VERSION "dbc-export 1 2025.20.8"

NS_ :

BS_:

BU_: DAS GTW HVP ICR PCS SCCM VCFRONT VCLEFT VCRIGHT VCSEC

BO_ 1001 DAS_bodyControls: 8 DAS
 SG_ DAS_headlightRequest : 0|2@1+ (1,0) [0|3] "" Vector__XXX
 SG_ DAS_hazardLightRequest : 2|2@1+ (1,0) [0|2] "" Vector__XXX
 SG_ DAS_wiperSpeed : 4|4@1+ (1,0) [0|15] "" Vector__XXX
 SG_ DAS_turnIndicatorRequest : 8|3@1+ (1,0) [0|7] "" Vector__XXX
 SG_ DAS_highLowBeamDecision : 11|2@1+ (1,0) [0|2] "" Vector__XXX
 SG_ DAS_heaterRequest : 13|2@1+ (1,0) [1|3] "" Vector__XXX
 SG_ DAS_highLowBeamOffReason : 15|3@1+ (1,0) [0|7] "" Vector__XXX
 SG_ DAS_forwardCamHeaterDutyCycle : 18|4@1+ (0.06666667,0) [0|1] "-" Vector__XXX
 SG_ DAS_dynamicBrakeLightRequest : 22|1@1+ (1,0) [0|1] "" Vector__XXX
 SG_ DAS_radarHeaterRequest : 23|1@1+ (1,0) [0|1] "" Vector__XXX
 SG_ DAS_ahlbOverride : 24|1@1+ (1,0) [0|1] "" Vector__XXX
 SG_ DAS_mirrorFoldRequest : 25|2@1+ (1,0) [0|2] "" Vector__XXX
 SG_ DAS_wiperWashRequest : 27|1@1+ (1,0) [0|1] "" Vector__XXX
 SG_ DAS_ulcConfirmationRequestActive : 28|1@1+ (1,0) [0|1] "" Vector__XXX
 SG_ DAS_overrideWiperSetting : 29|1@1+ (1,0) [0|1] "" Vector__XXX
 SG_ DAS_autoWiperState : 30|3@1+ (1,0) [0|7] "" Vector__XXX
 SG_ DAS_turnIndicatorRequestReason : 33|5@1+ (1,0) [0|31] "" Vector__XXX
 SG_ DAS_forwardRadarPowerRequest : 38|1@1+ (1,0) [0|1] "" Vector__XXX
 SG_ DAS_driverDomeLightRequest : 39|1@1+ (1,0) [0|1] "" Vector__XXX
 SG_ DAS_drivePowerStateRequest : 43|1@1+ (1,0) [0|1] "" Vector__XXX
 SG_ DAS_enableIcrDataCollection : 44|1@1+ (1,0) [0|1] "" Vector__XXX
 SG_ DAS_rPillarCamHeaterDutyCycle : 45|4@1+ (0.06666667,0) [0|1] "-" Vector__XXX
 SG_ DAS_adaptiveHighBeamIsFaulted : 49|1@1+ (1,0) [0|1] "" Vector__XXX
 SG_ DAS_restrictDoorReleaseLeft : 50|1@1+ (1,0) [0|1] "" Vector__XXX
 SG_ DAS_restrictDoorReleaseRight : 51|1@1+ (1,0) [0|1] "" Vector__XXX
 SG_ DAS_bodyControlsCounter : 52|4@1+ (1,0) [0|15] "" Vector__XXX
 SG_ DAS_bodyControlsChecksum : 56|8@1+ (1,0) [0|255] "" Vector__XXX

BO_ 784 HVP_info: 8 HVP
 SG_ HVP_infoIndex M : 0|8@1+ (1,0) [0|255] "" Vector__XXX
 SG_ HVP_buildType m10 : 8|3@1+ (1,0) [0|7] "" Vector__XXX
 SG_ HVP_buildConfigId m10 : 16|16@1+ (1,0) [0|65535] "" Vector__XXX
 SG_ HVP_hardwareId m10 : 32|16@1+ (1,0) [0|65535] "" Vector__XXX
 SG_ HVP_componentId m10 : 48|16@1+ (1,0) [0|65535] "" Vector__XXX
 SG_ HVP_pcbaId m11 : 16|8@1+ (1,0) [0|255] "" Vector__XXX
 SG_ HVP_assemblyId m11 : 24|8@1+ (1,0) [0|255] "" Vector__XXX
 SG_ HVP_usageId m11 : 32|16@1+ (1,0) [0|65535] "" Vector__XXX
 SG_ HVP_subUsageId m11 : 48|16@1+ (1,0) [0|65535] "" Vector__XXX
 SG_ HVP_platformType m13 : 8|8@1+ (1,0) [0|255] "" Vector__XXX
 SG_ HVP_appCrc m13 : 32|32@1+ (1,0) [0|4294967295] "" Vector__XXX
 SG_ HVP_appGitHash m17 : 8|56@1+ (1,0) [0|7.20575940379e+16] "" Vector__XXX
 SG_ HVP_bootGitHash m18 : 8|56@1+ (1,0) [0|7.20575940379e+16] "" Vector__XXX
 SG_ HVP_bootUdsProtoVersion m20 : 8|8@1+ (1,0) [0|255] "" Vector__XXX
 SG_ HVP_bootCrc m20 : 32|32@1+ (1,0) [0|4294967295] "" Vector__XXX

BO_ 941 ICR_info: 8 ICR
 SG_ ICR_infoIndex M : 0|8@1+ (1,0) [0|255] "" Vector__XXX
 SG_ ICR_infoBuildType m10 : 8|3@1+ (1,0) [0|7] "" Vector__XXX
 SG_ ICR_infoPcbaId m11 : 32|8@1+ (1,0) [0|255] "" Vector__XXX
 SG_ ICR_infoAssemblyId m11 : 40|8@1+ (1,0) [0|255] "" Vector__XXX
 SG_ ICR_infoUsageId m11 : 48|16@1+ (1,0) [0|65535] "" Vector__XXX
 SG_ ICR_infoAppCrc m13 : 8|32@1+ (1,0) [0|4294967295] "" Vector__XXX
 SG_ ICR_infoBoardPartNumber17 m25 : 8|56@1+ (1,0) [0|7.20575940379e+16] "" Vector__XXX
 SG_ ICR_infoBoardPartNumber814 m26 : 8|56@1+ (1,0) [0|7.20575940379e+16] "" Vector__XXX
 SG_ ICR_infoBoardPartNumber1520 m27 : 8|48@1+ (1,0) [0|281474976710655] "" Vector__XXX

BO_ 964 PCS_info: 8 PCS
 SG_ PCS_infoIndex M : 0|8@1+ (1,0) [0|255] "" Vector__XXX
 SG_ PCS_buildType m10 : 8|8@1+ (1,0) [0|255] "" Vector__XXX
 SG_ PCS_buildConfigId m10 : 16|16@1+ (1,0) [0|65535] "" Vector__XXX
 SG_ PCS_hardwareId m10 : 32|16@1+ (1,0) [0|65535] "" Vector__XXX
 SG_ PCS_componentId m10 : 48|16@1+ (1,0) [0|65535] "" Vector__XXX
 SG_ PCS_pcbaId m11 : 16|8@1+ (1,0) [0|255] "" Vector__XXX
 SG_ PCS_assemblyId m11 : 24|8@1+ (1,0) [0|255] "" Vector__XXX
 SG_ PCS_usageId m11 : 32|16@1+ (1,0) [0|65535] "" Vector__XXX
 SG_ PCS_subUsageId m11 : 48|16@1+ (1,0) [0|65535] "" Vector__XXX
 SG_ PCS_platformType m13 : 8|8@1+ (1,0) [0|255] "" Vector__XXX
 SG_ PCS_appCrc m13 : 32|32@1+ (1,0) [0|4294967295] "" Vector__XXX
 SG_ PCS_cpu2AppCrc m16 : 32|32@1+ (1,0) [0|4294967295] "" Vector__XXX
 SG_ PCS_appGitHash m17 : 8|56@1+ (1,0) [0|7.20575940379e+16] "" Vector__XXX
 SG_ PCS_bootGitHash m18 : 8|56@1+ (1,0) [0|7.20575940379e+16] "" Vector__XXX
 SG_ PCS_bootUdsProtoVersion m20 : 8|8@1+ (1,0) [0|255] "" Vector__XXX
 SG_ PCS_bootCrc m20 : 32|32@1+ (1,0) [0|4294967295] "" Vector__XXX

BO_ 816 SCCM_info: 8 SCCM
 SG_ SCCM_infoIndex M : 0|8@1+ (1,0) [0|255] "" Vector__XXX
 SG_ SCCM_infoBuildType m10 : 8|8@1+ (1,0) [0|255] "" Vector__XXX
 SG_ SCCM_infoBuildConfigId m10 : 16|16@1+ (1,0) [0|65535] "" Vector__XXX
 SG_ SCCM_infoHardwareId m10 : 32|16@1+ (1,0) [0|65535] "" Vector__XXX
 SG_ SCCM_infoComponentId m10 : 48|16@1+ (1,0) [0|65535] "" Vector__XXX
 SG_ SCCM_infoPcbaId m11 : 16|8@1+ (1,0) [0|255] "" Vector__XXX
 SG_ SCCM_infoAssemblyId m11 : 24|8@1+ (1,0) [0|255] "" Vector__XXX
 SG_ SCCM_infoUsageId m11 : 32|16@1+ (1,0) [0|65535] "" Vector__XXX
 SG_ SCCM_infoSubUsageId m11 : 48|16@1+ (1,0) [0|65535] "" Vector__XXX
 SG_ SCCM_infoPlatformType m13 : 8|8@1+ (1,0) [0|255] "" Vector__XXX
 SG_ SCCM_infoAppCrc m13 : 39|32@0+ (1,0) [0|4294967295] "" Vector__XXX
 SG_ SCCM_infoBootSvnRev m14 : 8|24@1+ (1,0) [0|16777215] "" Vector__XXX
 SG_ SCCM_infoBootSvnUrlHash m14 : 32|32@1+ (1,0) [0|4294967295] "" Vector__XXX
 SG_ SCCM_infoSubcomponent1Version m16 : 16|32@1+ (1,0) [0|4294967295] "" Vector__XXX
 SG_ SCCM_infoAppSvnHash m17 : 8|56@1+ (1,0) [0|7.20575940379e+16] "" Vector__XXX
 SG_ SCCM_infoBootSvnHash m18 : 8|56@1+ (1,0) [0|7.20575940379e+16] "" Vector__XXX
 SG_ SCCM_infoUdsProtoVersion m20 : 8|8@1+ (1,0) [0|255] "" Vector__XXX
 SG_ SCCM_infoBootCrc m20 : 32|32@1+ (1,0) [0|4294967295] "" Vector__XXX

BO_ 663 UI_suspensionControl: 8 GTW
 SG_ UI_adaptiveRideRequest : 3|2@1+ (1,0) [0|3] "" Vector__XXX
 SG_ UI_geofenceLevelingRequest : 7|3@1+ (1,0) [0|7] "" Vector__XXX

BO_ 957 VCFRONT_parkedEnergyLoss: 8 VCFRONT
 SG_ VCFRONT_energyLossIndex M : 0|3@1+ (1,0) [0|7] "" Vector__XXX
 SG_ VCFRONT_userEnergyLossSinceDrive m1 : 8|14@1+ (0.01,0) [0|163.83] "kWh" Vector__XXX
 SG_ VCFRONT_preconditioningEner_0001 m1 : 22|14@1+ (0.01,0) [0|163.83] "kWh" Vector__XXX
 SG_ VCFRONT_cabinOverheatEnergy_0001 m1 : 36|14@1+ (0.01,0) [0|163.83] "kWh" Vector__XXX
 SG_ VCFRONT_mobileAppEnergyLoss_0001 m1 : 50|14@1+ (0.01,0) [0|163.83] "kWh" Vector__XXX
 SG_ VCFRONT_summonStandbyEnergy_0001 m2 : 8|14@1+ (0.01,0) [0|163.83] "kWh" Vector__XXX
 SG_ VCFRONT_sentryModeEnergyLos_0001 m2 : 22|14@1+ (0.01,0) [0|163.83] "kWh" Vector__XXX
 SG_ VCFRONT_backgroundEnergyLos_0001 m2 : 36|14@1+ (0.01,0) [0|163.83] "kWh" Vector__XXX
 SG_ VCFRONT_evapDryingEnergyLos_0001 m2 : 50|14@1+ (0.01,0) [0|163.83] "kWh" Vector__XXX
 SG_ VCFRONT_userEnergyLossSinceCharg m3 : 8|14@1+ (0.01,0) [0|163.83] "kWh" Vector__XXX
 SG_ VCFRONT_preconditioningEnergyLos m3 : 22|14@1+ (0.01,0) [0|163.83] "kWh" Vector__XXX
 SG_ VCFRONT_cabinOverheatEnergyLossS m3 : 36|14@1+ (0.01,0) [0|163.83] "kWh" Vector__XXX
 SG_ VCFRONT_mobileAppEnergyLossSince m3 : 50|14@1+ (0.01,0) [0|163.83] "kWh" Vector__XXX
 SG_ VCFRONT_summonStandbyEnergyLossS m4 : 8|14@1+ (0.01,0) [0|163.83] "kWh" Vector__XXX
 SG_ VCFRONT_sentryModeEnergyLossSinc m4 : 22|14@1+ (0.01,0) [0|163.83] "kWh" Vector__XXX
 SG_ VCFRONT_backgroundEnergyLossSinc m4 : 36|14@1+ (0.01,0) [0|163.83] "kWh" Vector__XXX
 SG_ VCFRONT_evapDryingEnergyLossSinc m4 : 50|14@1+ (0.01,0) [0|163.83] "kWh" Vector__XXX

BO_ 507 VCLEFT_TLCStatus: 8 VCLEFT
 SG_ VCLEFT_TLCStatusIndex M : 0|2@1+ (1,0) [0|3] "" Vector__XXX
 SG_ VCLEFT_TLCTemperature m1 : 2|8@1- (1,68) [-59|195] "degC" Vector__XXX
 SG_ VCLEFT_TLCLeftTurnVoltage m1 : 10|8@1+ (0.1,0) [0|25.4] "V" Vector__XXX
 SG_ VCLEFT_TLCRightTurnVoltage m1 : 18|8@1+ (0.1,0) [0|25.4] "V" Vector__XXX
 SG_ VCLEFT_TLCState_LeftTurn m1 : 26|3@1+ (1,0) [0|7] "" Vector__XXX
 SG_ VCLEFT_TLCState_RightTurn m1 : 29|3@1+ (1,0) [0|7] "" Vector__XXX
 SG_ VCLEFT_TLCState_Tail m1 : 32|3@1+ (1,0) [0|7] "" Vector__XXX
 SG_ VCLEFT_TLCState_Stop m1 : 35|3@1+ (1,0) [0|7] "" Vector__XXX
 SG_ VCLEFT_TLCState_Fog m1 : 38|3@1+ (1,0) [0|7] "" Vector__XXX
 SG_ VCLEFT_TLCState_Reverse m1 : 41|3@1+ (1,0) [0|7] "" Vector__XXX

BO_ 291 VCRIGHT_doorStatus2: 8 VCRIGHT
 SG_ VCRIGHT_doorStatus2Index M : 0|1@1+ (1,0) [0|1] "" Vector__XXX
 SG_ VCRIGHT_frontLatchRelDuty m1 : 8|8@1+ (1,0) [0|255] "%" Vector__XXX
 SG_ VCRIGHT_BPillarCameraHeaterState m1 : 16|3@1+ (1,0) [1|7] "" Vector__XXX
 SG_ VCRIGHT_doorLatchAjarSwitchVolta m1 : 24|8@1+ (0.02,0) [0|5] "V" Vector__XXX
 SG_ VCRIGHT_doorLatchAjarSwitch_0001 m1 : 32|8@1+ (0.02,0) [0|5] "V" Vector__XXX
 SG_ VCRIGHT_BPillarCameraHeaterCurre m1 : 40|6@1+ (0.02,0) [0|1.24] "A" Vector__XXX
 SG_ VCRIGHT_mirrorTiltXOffset m1 : 48|8@1- (0.02,0) [-2.5|2.5] "V" Vector__XXX
 SG_ VCRIGHT_mirrorTiltYOffset m1 : 56|8@1- (0.02,0) [-2.5|2.5] "V" Vector__XXX

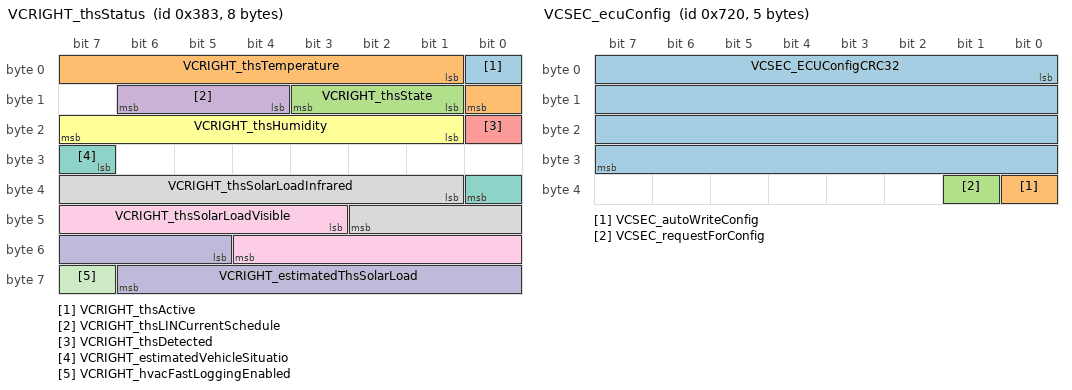
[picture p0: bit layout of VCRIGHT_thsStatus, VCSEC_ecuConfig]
BO_ 899 VCRIGHT_thsStatus: 8 VCRIGHT
 SG_ VCRIGHT_thsActive : 0|1@1+ (1,0) [0|1] "" Vector__XXX
 SG_ VCRIGHT_thsTemperature : 1|8@1+ (1,-40) [-40|150] "degC" Vector__XXX
 SG_ VCRIGHT_thsState : 9|3@1+ (1,0) [0|7] "" Vector__XXX
 SG_ VCRIGHT_thsLINCurrentSchedule : 12|3@1+ (1,0) [0|7] "" Vector__XXX
 SG_ VCRIGHT_thsDetected : 16|1@1+ (1,0) [0|1] "" Vector__XXX
 SG_ VCRIGHT_thsHumidity : 17|7@1+ (1,0) [0|100] "%" Vector__XXX
 SG_ VCRIGHT_estimatedVehicleSituatio : 31|2@1+ (1,0) [0|3] "" Vector__XXX
 SG_ VCRIGHT_thsSolarLoadInfrared : 33|10@1+ (2,0) [0|2044] "W/m2" Vector__XXX
 SG_ VCRIGHT_thsSolarLoadVisible : 43|10@1+ (2,0) [0|2044] "W/m2" Vector__XXX
 SG_ VCRIGHT_estimatedThsSolarLoad : 53|10@1+ (1,0) [0|1022] "W/m2" Vector__XXX
 SG_ VCRIGHT_hvacFastLoggingEnabled : 63|1@1+ (1,0) [0|1] "" Vector__XXX

BO_ 1066 VCSEC_TPMSConnectionData: 8 VCSEC
 SG_ VCSEC_TPMSSensorState0 : 0|3@1+ (1,0) [0|7] "" Vector__XXX
 SG_ VCSEC_TPMSRSSI0 : 3|7@1+ (1,-127) [-127|0] "dBm" Vector__XXX
 SG_ VCSEC_TPMSConnectionTypeCurrent0 : 10|2@1+ (1,0) [0|3] "" Vector__XXX
 SG_ VCSEC_TPMSConnectionTypeDesired0 : 12|2@1+ (1,0) [0|3] "" Vector__XXX
 SG_ VCSEC_TPMSSensorState1 : 14|3@1+ (1,0) [0|7] "" Vector__XXX
 SG_ VCSEC_TPMSRSSI1 : 17|7@1+ (1,-127) [-127|0] "dBm" Vector__XXX
 SG_ VCSEC_TPMSConnectionTypeCurrent1 : 24|2@1+ (1,0) [0|3] "" Vector__XXX
 SG_ VCSEC_TPMSConnectionTypeDesired1 : 26|2@1+ (1,0) [0|3] "" Vector__XXX
 SG_ VCSEC_TPMSSensorState2 : 28|3@1+ (1,0) [0|7] "" Vector__XXX
 SG_ VCSEC_TPMSRSSI2 : 31|7@1+ (1,-127) [-127|0] "dBm" Vector__XXX
 SG_ VCSEC_TPMSConnectionTypeCurrent2 : 38|2@1+ (1,0) [0|3] "" Vector__XXX
 SG_ VCSEC_TPMSConnectionTypeDesired2 : 40|2@1+ (1,0) [0|3] "" Vector__XXX
 SG_ VCSEC_TPMSSensorState3 : 42|3@1+ (1,0) [0|7] "" Vector__XXX
 SG_ VCSEC_TPMSRSSI3 : 45|7@1+ (1,-127) [-127|0] "dBm" Vector__XXX
 SG_ VCSEC_TPMSConnectionTypeCurrent3 : 52|2@1+ (1,0) [0|3] "" Vector__XXX
 SG_ VCSEC_TPMSConnectionTypeDesired3 : 54|2@1+ (1,0) [0|3] "" Vector__XXX
 SG_ VCSEC_TPMSSensorPresence0 : 56|2@1+ (1,0) [0|3] "" Vector__XXX
 SG_ VCSEC_TPMSSensorPresence1 : 58|2@1+ (1,0) [0|3] "" Vector__XXX
 SG_ VCSEC_TPMSSensorPresence2 : 60|2@1+ (1,0) [0|3] "" Vector__XXX
 SG_ VCSEC_TPMSSensorPresence3 : 62|2@1+ (1,0) [0|3] "" Vector__XXX

BO_ 1824 VCSEC_ecuConfig: 5 VCSEC
 SG_ VCSEC_ECUConfigCRC32 : 0|32@1+ (1,0) [0|4294967295] "" Vector__XXX
 SG_ VCSEC_autoWriteConfig : 32|1@1+ (1,0) [0|1] "" Vector__XXX
 SG_ VCSEC_requestForConfig : 33|1@1+ (1,0) [0|1] "" Vector__XXX

BO_TX_BU_ 1001 : DAS;
BO_TX_BU_ 784 : HVP;
BO_TX_BU_ 941 : ICR;
BO_TX_BU_ 964 : PCS;
BO_TX_BU_ 816 : SCCM;
BO_TX_BU_ 663 : GTW;
BO_TX_BU_ 957 : VCFRONT;
BO_TX_BU_ 507 : VCLEFT;
BO_TX_BU_ 291 : VCRIGHT;
BO_TX_BU_ 899 : VCRIGHT;
BO_TX_BU_ 1066 : VCSEC;
BO_TX_BU_ 1824 : VCSEC;

CM_ "Tesla Model Y CAN bus database; bus VEH (vehicle CAN); firmware 2025.20.8. Decoded CAN signal definitions (layout, scaling, units, value tables).";
CM_ BU_ DAS "Driver assistance computer";
CM_ BU_ GTW "Gateway";
CM_ BU_ HVP "High-voltage processor (pack contactor and isolation controller)";
CM_ BU_ ICR "ICR ECU";
CM_ BU_ PCS "Power conversion system (on-board charger and DC-DC converter)";
CM_ BU_ SCCM "Steering column control module";
CM_ BU_ VCFRONT "Front body controller";
CM_ BU_ VCLEFT "Left body controller";
CM_ BU_ VCRIGHT "Right body controller";
CM_ BU_ VCSEC "Vehicle security controller";
CM_ BO_ 1001 "Driver assistance computer message: body controls";
CM_ SG_ 1001 DAS_headlightRequest "The DAS request to the body controls ecu to turn on headlights.";
CM_ SG_ 1001 DAS_hazardLightRequest "The command from DAS to body controls to turn on the hazard lights; raw 3 = signal not available (SNA)";
CM_ SG_ 1001 DAS_wiperSpeed "The auto wiper algorithm speed request to the body controller.";
CM_ SG_ 1001 DAS_turnIndicatorRequest "Reports Driver Assistance System (DAS) request to body controls to turn on/off the left or right turn indicator.";
CM_ SG_ 1001 DAS_highLowBeamDecision "The output of the automatic high beam algorithm, to turn the highbeams on or off; raw 3 = signal not available (SNA)";
CM_ SG_ 1001 DAS_heaterRequest "The DAS request to the body controller to turn on the front glass heater in front of the triple camera; raw 0 = signal not available (SNA)";
CM_ SG_ 1001 DAS_highLowBeamOffReason "The reason why automatic high beams are surpressed; raw 5 = signal not available (SNA)";
CM_ SG_ 1001 DAS_forwardCamHeaterDutyCycle "Supplies the requested duty cycle of the front windshield camera heater";
CM_ SG_ 1001 DAS_dynamicBrakeLightRequest "Indicates if the dynamic brake light alogirthm is requesting pulsing brake lights.";
CM_ SG_ 1001 DAS_radarHeaterRequest "Reports the request from Driver Assistance System (DAS) to body controls to turn on heater to clear out fascia in front of the radar.";
CM_ SG_ 1001 DAS_ahlbOverride "Indicates if body controller should override UI switch and stalk state to allow auto high beam functionality";
CM_ SG_ 1001 DAS_mirrorFoldRequest "DAS request to fold or present mirrors; raw 3 = signal not available (SNA)";
CM_ SG_ 1001 DAS_wiperWashRequest "Autowiper requests that the windshield be washed";
CM_ SG_ 1001 DAS_ulcConfirmationRequestActive "Driver assistance computer: ulc confirmation request active";
CM_ SG_ 1001 DAS_overrideWiperSetting "Autopilot wants to override the user's wiper setting to enable auto-wiper";
CM_ SG_ 1001 DAS_autoWiperState "DAS auto wiper internal state; raw 5 = signal not available (SNA)";
CM_ SG_ 1001 DAS_turnIndicatorRequestReason "Reports the reason that Driver Assistance System (DAS) is requesting a change to the turn indicator state from body controls.";
CM_ SG_ 1001 DAS_forwardRadarPowerRequest "Driver assistance computer: forward radar power request";
CM_ SG_ 1001 DAS_driverDomeLightRequest "DAS requests that driver side dome light be illuminated";
CM_ SG_ 1001 DAS_drivePowerStateRequest "Reports DAS request for vehicle power state Drive.";
CM_ SG_ 1001 DAS_enableIcrDataCollection "Driver assistance computer: enable icr data collection";
CM_ SG_ 1001 DAS_rPillarCamHeaterDutyCycle "Supplies the requested duty cycle of the right pillar camera heater";
CM_ SG_ 1001 DAS_adaptiveHighBeamIsFaulted "Indicates malfunctioning or unavailable input to the Adaptive High Beam system.";
CM_ SG_ 1001 DAS_restrictDoorReleaseLeft "Reports requests to inhibit left doors from being released.";
CM_ SG_ 1001 DAS_restrictDoorReleaseRight "Reports requests to inhibit right doors from being released.";
CM_ SG_ 1001 DAS_bodyControlsCounter "Driver assistance computer: body controls counter";
CM_ SG_ 1001 DAS_bodyControlsChecksum "Driver assistance computer: body controls checksum";
CM_ BO_ 784 "High-voltage processor (pack contactor and isolation controller) message: info";
CM_ SG_ 784 HVP_infoIndex "High-voltage processor (pack contactor and isolation controller): info index";
CM_ SG_ 784 HVP_buildType "High-voltage processor (pack contactor and isolation controller): build type";
CM_ SG_ 784 HVP_buildConfigId "High-voltage processor (pack contactor and isolation controller): build config id";
CM_ SG_ 784 HVP_hardwareId "High-voltage processor (pack contactor and isolation controller): hardware id";
CM_ SG_ 784 HVP_componentId "High-voltage processor (pack contactor and isolation controller): component id";
CM_ SG_ 784 HVP_pcbaId "High-voltage processor (pack contactor and isolation controller): pcba id";
CM_ SG_ 784 HVP_assemblyId "HVP's assigned assembly ID";
CM_ SG_ 784 HVP_usageId "HVP's assigned usage ID";
CM_ SG_ 784 HVP_subUsageId "HVP's assigned subusage ID";
CM_ SG_ 784 HVP_platformType "High-voltage processor (pack contactor and isolation controller): platform type";
CM_ SG_ 784 HVP_appCrc "High-voltage processor (pack contactor and isolation controller): app crc";
CM_ SG_ 784 HVP_appGitHash "High-voltage processor (pack contactor and isolation controller): app git hash";
CM_ SG_ 784 HVP_bootGitHash "High-voltage processor (pack contactor and isolation controller): boot git hash";
CM_ SG_ 784 HVP_bootUdsProtoVersion "High-voltage processor (pack contactor and isolation controller): boot uds proto version";
CM_ SG_ 784 HVP_bootCrc "High-voltage processor (pack contactor and isolation controller): boot crc";
CM_ BO_ 941 "ICR ECU message: info";
CM_ SG_ 941 ICR_infoIndex "ICR ECU: info index";
CM_ SG_ 941 ICR_infoBuildType "ICR ECU: info build type";
CM_ SG_ 941 ICR_infoPcbaId "ICR ECU: info pcba id";
CM_ SG_ 941 ICR_infoAssemblyId "ICR ECU: info assembly id";
CM_ SG_ 941 ICR_infoUsageId "ICR ECU: info usage id";
CM_ SG_ 941 ICR_infoAppCrc "ICR ECU: info app crc";
CM_ SG_ 941 ICR_infoBoardPartNumber17 "ICR ECU: info board part number17";
CM_ SG_ 941 ICR_infoBoardPartNumber814 "ICR ECU: info board part number814";
CM_ SG_ 941 ICR_infoBoardPartNumber1520 "ICR ECU: info board part number1520";
CM_ BO_ 964 "Power conversion system (on-board charger and DC-DC converter) message: info";
CM_ SG_ 964 PCS_infoIndex "Power conversion system (on-board charger and DC-DC converter): info index";
CM_ SG_ 964 PCS_buildType "Power conversion system (on-board charger and DC-DC converter): build type";
CM_ SG_ 964 PCS_buildConfigId "Power conversion system (on-board charger and DC-DC converter): build config id";
CM_ SG_ 964 PCS_hardwareId "Power conversion system (on-board charger and DC-DC converter): hardware id";
CM_ SG_ 964 PCS_componentId "Power conversion system (on-board charger and DC-DC converter): component id";
CM_ SG_ 964 PCS_pcbaId "PCBA ID portion of component hardware ID as reported by application";
CM_ SG_ 964 PCS_assemblyId "Power conversion system (on-board charger and DC-DC converter): assembly id";
CM_ SG_ 964 PCS_usageId "Usage ID portion of component hardware ID as reported by application";
CM_ SG_ 964 PCS_subUsageId "Sub-usage ID portion of component hardware ID as reported by application";
CM_ SG_ 964 PCS_platformType "Power conversion system (on-board charger and DC-DC converter): platform type";
CM_ SG_ 964 PCS_appCrc "Power conversion system (on-board charger and DC-DC converter): app crc";
CM_ SG_ 964 PCS_cpu2AppCrc "Power conversion system (on-board charger and DC-DC converter): cpu2 app crc";
CM_ SG_ 964 PCS_appGitHash "Power conversion system (on-board charger and DC-DC converter): app git hash";
CM_ SG_ 964 PCS_bootGitHash "Power conversion system (on-board charger and DC-DC converter): boot git hash";
CM_ SG_ 964 PCS_bootUdsProtoVersion "Power conversion system (on-board charger and DC-DC converter): boot uds proto version";
CM_ SG_ 964 PCS_bootCrc "Power conversion system (on-board charger and DC-DC converter): boot crc";
CM_ BO_ 816 "Steering column control module message: info";
CM_ SG_ 816 SCCM_infoIndex "Steering column control module: info index";
CM_ SG_ 816 SCCM_infoBuildType "Steering column control module: info build type";
CM_ SG_ 816 SCCM_infoBuildConfigId "Steering column control module: info build config id";
CM_ SG_ 816 SCCM_infoHardwareId "Steering column control module: info hardware id";
CM_ SG_ 816 SCCM_infoComponentId "Steering column control module: info component id";
CM_ SG_ 816 SCCM_infoPcbaId "Steering column control module: info pcba id";
CM_ SG_ 816 SCCM_infoAssemblyId "Steering column control module: info assembly id";
CM_ SG_ 816 SCCM_infoUsageId "Steering column control module: info usage id";
CM_ SG_ 816 SCCM_infoSubUsageId "Steering column control module: info sub usage id";
CM_ SG_ 816 SCCM_infoPlatformType "Steering column control module: info platform type";
CM_ SG_ 816 SCCM_infoAppCrc "Steering column control module: info app crc";
CM_ SG_ 816 SCCM_infoBootSvnRev "Steering column control module: info boot svn rev";
CM_ SG_ 816 SCCM_infoBootSvnUrlHash "Steering column control module: info boot svn url hash";
CM_ SG_ 816 SCCM_infoSubcomponent1Version "Steering column control module: info subcomponent1 version";
CM_ SG_ 816 SCCM_infoAppSvnHash "Steering column control module: info app svn hash";
CM_ SG_ 816 SCCM_infoBootSvnHash "Steering column control module: info boot svn hash";
CM_ SG_ 816 SCCM_infoUdsProtoVersion "Steering column control module: info uds proto version";
CM_ SG_ 816 SCCM_infoBootCrc "Steering column control module: info boot crc";
CM_ BO_ 663 "Touchscreen user interface computer message: suspension control; forwarded onto this bus by the gateway";
CM_ SG_ 663 UI_adaptiveRideRequest "UI customer adaptive ride request for air suspension.";
CM_ SG_ 663 UI_geofenceLevelingRequest "Geofence level request from customer; raw 5 = signal not available (SNA)";
CM_ BO_ 957 "Front body controller message: parked energy loss";
CM_ SG_ 957 VCFRONT_energyLossIndex "Front body controller: energy loss index";
CM_ SG_ 957 VCFRONT_userEnergyLossSinceDrive "Energy loss due to user interaction since last drive";
CM_ SG_ 957 VCFRONT_preconditioningEner_0001 "Energy loss due to preconditioning since last drive";
CM_ SG_ 957 VCFRONT_cabinOverheatEnergy_0001 "Energy loss due to cabin overheat protection since last drive";
CM_ SG_ 957 VCFRONT_mobileAppEnergyLoss_0001 "Energy loss due to mobile app interaction since last drive";
CM_ SG_ 957 VCFRONT_summonStandbyEnergy_0001 "Energy loss due to summon standby since last drive";
CM_ SG_ 957 VCFRONT_sentryModeEnergyLos_0001 "Energy loss due to sentry mode since last drive";
CM_ SG_ 957 VCFRONT_backgroundEnergyLos_0001 "Energy loss due to background vehicle op since last drive";
CM_ SG_ 957 VCFRONT_evapDryingEnergyLos_0001 "Energy loss due to evap drying since last drive";
CM_ SG_ 957 VCFRONT_userEnergyLossSinceCharg "Energy loss due to user interaction since last charge";
CM_ SG_ 957 VCFRONT_preconditioningEnergyLos "Energy loss due to preconditioning since last charge";
CM_ SG_ 957 VCFRONT_cabinOverheatEnergyLossS "Energy loss due to cabin overheat protection since last charge";
CM_ SG_ 957 VCFRONT_mobileAppEnergyLossSince "Energy loss due to mobile app interaction since last charge";
CM_ SG_ 957 VCFRONT_summonStandbyEnergyLossS "Energy loss due to summon standby since last charge";
CM_ SG_ 957 VCFRONT_sentryModeEnergyLossSinc "Energy loss due to sentry mode since last charge";
CM_ SG_ 957 VCFRONT_backgroundEnergyLossSinc "Energy loss due to background vehicle op since last charge";
CM_ SG_ 957 VCFRONT_evapDryingEnergyLossSinc "Energy loss due to evap drying since last charge";
CM_ BO_ 507 "Left body controller message: TLC status";
CM_ SG_ 507 VCLEFT_TLCStatusIndex "Left body controller: TLC status index";
CM_ SG_ 507 VCLEFT_TLCTemperature "Monitors board temperatures for electrical validation; raw 128 = signal not available (SNA)";
CM_ SG_ 507 VCLEFT_TLCLeftTurnVoltage "Reports voltage for analysis of in field issues; raw 255 = signal not available (SNA)";
CM_ SG_ 507 VCLEFT_TLCRightTurnVoltage "Reports voltage for analysis of in field issues; raw 255 = signal not available (SNA)";
CM_ SG_ 507 VCLEFT_TLCState_LeftTurn "Reports trailer light status; raw 5 = signal not available (SNA)";
CM_ SG_ 507 VCLEFT_TLCState_RightTurn "Reports trailer light status; raw 5 = signal not available (SNA)";
CM_ SG_ 507 VCLEFT_TLCState_Tail "Reports trailer light status; raw 5 = signal not available (SNA)";
CM_ SG_ 507 VCLEFT_TLCState_Stop "Reports trailer light status; raw 5 = signal not available (SNA)";
CM_ SG_ 507 VCLEFT_TLCState_Fog "Reports trailer light status; raw 5 = signal not available (SNA)";
CM_ SG_ 507 VCLEFT_TLCState_Reverse "Reports trailer light status; raw 5 = signal not available (SNA)";
CM_ BO_ 291 "Right body controller message: door status2";
CM_ SG_ 291 VCRIGHT_doorStatus2Index "Right body controller: door status2 index";
CM_ SG_ 291 VCRIGHT_frontLatchRelDuty "Front left door latch motor duty cycle.";
CM_ SG_ 291 VCRIGHT_BPillarCameraHeaterState "Indicates the state of the right b-pillar camera heater; raw 0 = signal not available (SNA)";
CM_ SG_ 291 VCRIGHT_doorLatchAjarSwitchVolta "Door latch switch voltage feeding switch logic";
CM_ SG_ 291 VCRIGHT_doorLatchAjarSwitch_0001 "Door latch switch voltage feeding switch logic";
CM_ SG_ 291 VCRIGHT_BPillarCameraHeaterCurre "Current drawn by the right b-pillar camera heater; raw 63 = signal not available (SNA)";
CM_ SG_ 291 VCRIGHT_mirrorTiltXOffset "Communicates post calibration position offset of right side view mirror tilt horizontal position";
CM_ SG_ 291 VCRIGHT_mirrorTiltYOffset "Communicates post calibration position offset of right side view mirror tilt vertical position";
CM_ BO_ 899 "Right body controller message: ths status";
CM_ SG_ 899 VCRIGHT_thsActive "Right body controller: ths active";
CM_ SG_ 899 VCRIGHT_thsTemperature "Tesla HVAC sensor temperature; raw 255 = signal not available (SNA)";
CM_ SG_ 899 VCRIGHT_thsState "Right body controller: ths state";
CM_ SG_ 899 VCRIGHT_thsLINCurrentSchedule "Right body controller: ths LIN current schedule";
CM_ SG_ 899 VCRIGHT_thsDetected "Tesla HVAC sensor connection is detected";
CM_ SG_ 899 VCRIGHT_thsHumidity "Tesla HVAC sensor humidity; raw 127 = signal not available (SNA)";
CM_ SG_ 899 VCRIGHT_estimatedVehicleSituatio "Right body controller: estimated vehicle situation";
CM_ SG_ 899 VCRIGHT_thsSolarLoadInfrared "Solar power hitting the vehicle in the infrared spectrum; raw 1023 = signal not available (SNA)";
CM_ SG_ 899 VCRIGHT_thsSolarLoadVisible "Solar power hitting the vehicle in the visible spectrum; raw 1023 = signal not available (SNA)";
CM_ SG_ 899 VCRIGHT_estimatedThsSolarLoad "Right body controller: estimated ths solar load; raw 1023 = signal not available (SNA)";
CM_ SG_ 899 VCRIGHT_hvacFastLoggingEnabled "Right body controller: hvac fast logging enabled";
CM_ BO_ 1066 "Vehicle security controller message: TPMS connection data";
CM_ SG_ 1066 VCSEC_TPMSSensorState0 "Indicates the sensors pairing/connectivity status";
CM_ SG_ 1066 VCSEC_TPMSRSSI0 "Received Signal Strength Index reported by sensor.";
CM_ SG_ 1066 VCSEC_TPMSConnectionTypeCurrent0 "Vehicle security controller: TPMS connection type current0";
CM_ SG_ 1066 VCSEC_TPMSConnectionTypeDesired0 "Vehicle security controller: TPMS connection type desired0";
CM_ SG_ 1066 VCSEC_TPMSSensorState1 "Indicates the sensors pairing/connectivity status";
CM_ SG_ 1066 VCSEC_TPMSRSSI1 "Received Signal Strength Index reported by sensor.";
CM_ SG_ 1066 VCSEC_TPMSConnectionTypeCurrent1 "Vehicle security controller: TPMS connection type current1";
CM_ SG_ 1066 VCSEC_TPMSConnectionTypeDesired1 "Vehicle security controller: TPMS connection type desired1";
CM_ SG_ 1066 VCSEC_TPMSSensorState2 "Indicates the sensors pairing/connectivity status";
CM_ SG_ 1066 VCSEC_TPMSRSSI2 "Received Signal Strength Index reported by sensor.";
CM_ SG_ 1066 VCSEC_TPMSConnectionTypeCurrent2 "Vehicle security controller: TPMS connection type current2";
CM_ SG_ 1066 VCSEC_TPMSConnectionTypeDesired2 "Vehicle security controller: TPMS connection type desired2";
CM_ SG_ 1066 VCSEC_TPMSSensorState3 "Indicates the sensors pairing/connectivity status";
CM_ SG_ 1066 VCSEC_TPMSRSSI3 "Received Signal Strength Index reported by sensor.";
CM_ SG_ 1066 VCSEC_TPMSConnectionTypeCurrent3 "Vehicle security controller: TPMS connection type current3";
CM_ SG_ 1066 VCSEC_TPMSConnectionTypeDesired3 "Vehicle security controller: TPMS connection type desired3";
CM_ SG_ 1066 VCSEC_TPMSSensorPresence0 "Indicates the sensors detection status";
CM_ SG_ 1066 VCSEC_TPMSSensorPresence1 "Indicates the sensors detection status";
CM_ SG_ 1066 VCSEC_TPMSSensorPresence2 "Indicates the sensors detection status";
CM_ SG_ 1066 VCSEC_TPMSSensorPresence3 "Indicates the sensors detection status";
CM_ BO_ 1824 "Vehicle security controller message: ecu config";
CM_ SG_ 1824 VCSEC_ECUConfigCRC32 "Vehicle security controller: ECU config CRC32";
CM_ SG_ 1824 VCSEC_autoWriteConfig "Vehicle security controller: auto write config";
CM_ SG_ 1824 VCSEC_requestForConfig "Vehicle security controller: request for config";
BA_DEF_ "BusType" STRING;
BA_DEF_ "DBName" STRING;
BA_DEF_ "Baudrate" INT 0 1000000;
BA_DEF_ "BaudrateCANFD" INT 0 16000000;
BA_DEF_ "Manufacturer" STRING;
BA_DEF_ "FirmwareVersion" STRING;
BA_DEF_ "VehicleModel" STRING;
BA_DEF_ BU_ "ECU" STRING;
BA_DEF_ BO_ "GenMsgCycleTime" INT 0 3600000;
BA_DEF_ BO_ "GenMsgSendType" ENUM "Cyclic","NotUsed","NotUsed","NotUsed","NotUsed","NotUsed","NotUsed","IfActive","NoMsgSendType","NotUsed";
BA_DEF_ BO_ "VFrameFormat" ENUM "StandardCAN","ExtendedCAN","reserved","J1939PG","reserved","reserved","reserved","reserved","reserved","reserved","reserved","reserved","reserved","reserved","StandardCAN_FD","ExtendedCAN_FD";
BA_DEF_ BO_ "CANFD_BRS" ENUM "0","1";
BA_DEF_ SG_ "GenSigSNA" STRING;
BA_DEF_ SG_ "SystemSignalLongSymbol" STRING;
BA_DEF_ SG_ "Confidence" ENUM "validated","plausible","layout-only","contradicted";
BA_DEF_DEF_ "BusType" "CAN";
BA_DEF_DEF_ "DBName" "";
BA_DEF_DEF_ "Baudrate" 500000;
BA_DEF_DEF_ "BaudrateCANFD" 2000000;
BA_DEF_DEF_ "Manufacturer" "";
BA_DEF_DEF_ "FirmwareVersion" "";
BA_DEF_DEF_ "VehicleModel" "";
BA_DEF_DEF_ "ECU" "";
BA_DEF_DEF_ "GenMsgCycleTime" 0;
BA_DEF_DEF_ "GenMsgSendType" "NoMsgSendType";
BA_DEF_DEF_ "VFrameFormat" "StandardCAN";
BA_DEF_DEF_ "CANFD_BRS" "1";
BA_DEF_DEF_ "GenSigSNA" "";
BA_DEF_DEF_ "SystemSignalLongSymbol" "";
BA_DEF_DEF_ "Confidence" "layout-only";
BA_ "DBName" "ModelY_VEH";
BA_ "Manufacturer" "Tesla";
BA_ "FirmwareVersion" "2025.20.8";
BA_ "VehicleModel" "Model Y";
BA_ "ECU" BU_ DAS "DAS";
BA_ "ECU" BU_ GTW "GTW";
BA_ "ECU" BU_ HVP "HVP";
BA_ "ECU" BU_ ICR "ICR";
BA_ "ECU" BU_ PCS "PCS";
BA_ "ECU" BU_ SCCM "SCCM";
BA_ "ECU" BU_ VCFRONT "VCFRONT";
BA_ "ECU" BU_ VCLEFT "VCLEFT";
BA_ "ECU" BU_ VCRIGHT "VCRIGHT";
BA_ "ECU" BU_ VCSEC "VCSEC";
BA_ "GenMsgCycleTime" BO_ 1001 500;
BA_ "GenMsgSendType" BO_ 1001 0;
BA_ "GenMsgCycleTime" BO_ 784 10000;
BA_ "GenMsgSendType" BO_ 784 0;
BA_ "GenMsgCycleTime" BO_ 941 10000;
BA_ "GenMsgSendType" BO_ 941 0;
BA_ "GenMsgCycleTime" BO_ 964 1000;
BA_ "GenMsgSendType" BO_ 964 0;
BA_ "GenMsgCycleTime" BO_ 816 1000;
BA_ "GenMsgSendType" BO_ 816 0;
BA_ "GenMsgCycleTime" BO_ 663 500;
BA_ "GenMsgSendType" BO_ 663 0;
BA_ "GenMsgCycleTime" BO_ 957 1000;
BA_ "GenMsgSendType" BO_ 957 0;
BA_ "GenMsgCycleTime" BO_ 507 50;
BA_ "GenMsgSendType" BO_ 507 0;
BA_ "GenMsgCycleTime" BO_ 291 100;
BA_ "GenMsgSendType" BO_ 291 0;
BA_ "GenMsgCycleTime" BO_ 899 100;
BA_ "GenMsgSendType" BO_ 899 0;
BA_ "GenMsgCycleTime" BO_ 1066 100;
BA_ "GenMsgSendType" BO_ 1066 0;
BA_ "GenMsgCycleTime" BO_ 1824 10000;
BA_ "GenMsgSendType" BO_ 1824 0;
BA_ "Confidence" SG_ 1001 DAS_headlightRequest 0;
BA_ "Confidence" SG_ 1001 DAS_hazardLightRequest 0;
BA_ "GenSigSNA" SG_ 1001 DAS_hazardLightRequest "3";
BA_ "Confidence" SG_ 1001 DAS_wiperSpeed 0;
BA_ "Confidence" SG_ 1001 DAS_turnIndicatorRequest 0;
BA_ "Confidence" SG_ 1001 DAS_highLowBeamDecision 0;
BA_ "GenSigSNA" SG_ 1001 DAS_highLowBeamDecision "3";
BA_ "Confidence" SG_ 1001 DAS_heaterRequest 0;
BA_ "GenSigSNA" SG_ 1001 DAS_heaterRequest "0";
BA_ "Confidence" SG_ 1001 DAS_highLowBeamOffReason 0;
BA_ "GenSigSNA" SG_ 1001 DAS_highLowBeamOffReason "5";
BA_ "Confidence" SG_ 1001 DAS_forwardCamHeaterDutyCycle 0;
BA_ "Confidence" SG_ 1001 DAS_dynamicBrakeLightRequest 0;
BA_ "Confidence" SG_ 1001 DAS_radarHeaterRequest 0;
BA_ "Confidence" SG_ 1001 DAS_ahlbOverride 0;
BA_ "Confidence" SG_ 1001 DAS_mirrorFoldRequest 0;
BA_ "GenSigSNA" SG_ 1001 DAS_mirrorFoldRequest "3";
BA_ "Confidence" SG_ 1001 DAS_wiperWashRequest 0;
BA_ "Confidence" SG_ 1001 DAS_ulcConfirmationRequestActive 0;
BA_ "Confidence" SG_ 1001 DAS_overrideWiperSetting 0;
BA_ "Confidence" SG_ 1001 DAS_autoWiperState 0;
BA_ "GenSigSNA" SG_ 1001 DAS_autoWiperState "5";
BA_ "Confidence" SG_ 1001 DAS_turnIndicatorRequestReason 0;
BA_ "Confidence" SG_ 1001 DAS_forwardRadarPowerRequest 0;
BA_ "Confidence" SG_ 1001 DAS_driverDomeLightRequest 0;
BA_ "Confidence" SG_ 1001 DAS_drivePowerStateRequest 0;
BA_ "Confidence" SG_ 1001 DAS_enableIcrDataCollection 0;
BA_ "Confidence" SG_ 1001 DAS_rPillarCamHeaterDutyCycle 0;
BA_ "Confidence" SG_ 1001 DAS_adaptiveHighBeamIsFaulted 0;
BA_ "Confidence" SG_ 1001 DAS_restrictDoorReleaseLeft 0;
BA_ "Confidence" SG_ 1001 DAS_restrictDoorReleaseRight 0;
BA_ "Confidence" SG_ 1001 DAS_bodyControlsCounter 0;
BA_ "Confidence" SG_ 1001 DAS_bodyControlsChecksum 0;
BA_ "Confidence" SG_ 784 HVP_infoIndex 1;
BA_ "Confidence" SG_ 784 HVP_buildType 0;
BA_ "Confidence" SG_ 784 HVP_buildConfigId 0;
BA_ "Confidence" SG_ 784 HVP_hardwareId 0;
BA_ "Confidence" SG_ 784 HVP_componentId 0;
BA_ "Confidence" SG_ 784 HVP_pcbaId 0;
BA_ "Confidence" SG_ 784 HVP_assemblyId 0;
BA_ "Confidence" SG_ 784 HVP_usageId 0;
BA_ "Confidence" SG_ 784 HVP_subUsageId 0;
BA_ "Confidence" SG_ 784 HVP_platformType 0;
BA_ "Confidence" SG_ 784 HVP_appCrc 0;
BA_ "Confidence" SG_ 784 HVP_appGitHash 0;
BA_ "Confidence" SG_ 784 HVP_bootGitHash 0;
BA_ "Confidence" SG_ 784 HVP_bootUdsProtoVersion 0;
BA_ "Confidence" SG_ 784 HVP_bootCrc 0;
BA_ "Confidence" SG_ 941 ICR_infoIndex 1;
BA_ "Confidence" SG_ 941 ICR_infoBuildType 0;
BA_ "Confidence" SG_ 941 ICR_infoPcbaId 0;
BA_ "Confidence" SG_ 941 ICR_infoAssemblyId 0;
BA_ "Confidence" SG_ 941 ICR_infoUsageId 0;
BA_ "Confidence" SG_ 941 ICR_infoAppCrc 0;
BA_ "Confidence" SG_ 941 ICR_infoBoardPartNumber17 0;
BA_ "Confidence" SG_ 941 ICR_infoBoardPartNumber814 0;
BA_ "Confidence" SG_ 941 ICR_infoBoardPartNumber1520 0;
BA_ "Confidence" SG_ 964 PCS_infoIndex 1;
BA_ "Confidence" SG_ 964 PCS_buildType 0;
BA_ "Confidence" SG_ 964 PCS_buildConfigId 0;
BA_ "Confidence" SG_ 964 PCS_hardwareId 0;
BA_ "Confidence" SG_ 964 PCS_componentId 0;
BA_ "Confidence" SG_ 964 PCS_pcbaId 0;
BA_ "Confidence" SG_ 964 PCS_assemblyId 0;
BA_ "Confidence" SG_ 964 PCS_usageId 0;
BA_ "Confidence" SG_ 964 PCS_subUsageId 0;
BA_ "Confidence" SG_ 964 PCS_platformType 0;
BA_ "Confidence" SG_ 964 PCS_appCrc 0;
BA_ "Confidence" SG_ 964 PCS_cpu2AppCrc 0;
BA_ "Confidence" SG_ 964 PCS_appGitHash 0;
BA_ "Confidence" SG_ 964 PCS_bootGitHash 0;
BA_ "Confidence" SG_ 964 PCS_bootUdsProtoVersion 0;
BA_ "Confidence" SG_ 964 PCS_bootCrc 0;
BA_ "Confidence" SG_ 816 SCCM_infoIndex 1;
BA_ "Confidence" SG_ 816 SCCM_infoBuildType 0;
BA_ "Confidence" SG_ 816 SCCM_infoBuildConfigId 0;
BA_ "Confidence" SG_ 816 SCCM_infoHardwareId 0;
BA_ "Confidence" SG_ 816 SCCM_infoComponentId 0;
BA_ "Confidence" SG_ 816 SCCM_infoPcbaId 0;
BA_ "Confidence" SG_ 816 SCCM_infoAssemblyId 0;
BA_ "Confidence" SG_ 816 SCCM_infoUsageId 0;
BA_ "Confidence" SG_ 816 SCCM_infoSubUsageId 0;
BA_ "Confidence" SG_ 816 SCCM_infoPlatformType 0;
BA_ "Confidence" SG_ 816 SCCM_infoBootSvnRev 0;
BA_ "Confidence" SG_ 816 SCCM_infoBootSvnUrlHash 0;
BA_ "Confidence" SG_ 816 SCCM_infoSubcomponent1Version 0;
BA_ "Confidence" SG_ 816 SCCM_infoAppSvnHash 0;
BA_ "Confidence" SG_ 816 SCCM_infoBootSvnHash 0;
BA_ "Confidence" SG_ 816 SCCM_infoUdsProtoVersion 0;
BA_ "Confidence" SG_ 816 SCCM_infoBootCrc 0;
BA_ "Confidence" SG_ 663 UI_adaptiveRideRequest 0;
BA_ "Confidence" SG_ 663 UI_geofenceLevelingRequest 0;
BA_ "GenSigSNA" SG_ 663 UI_geofenceLevelingRequest "5";
BA_ "Confidence" SG_ 957 VCFRONT_energyLossIndex 1;
BA_ "Confidence" SG_ 957 VCFRONT_userEnergyLossSinceDrive 0;
BA_ "Confidence" SG_ 957 VCFRONT_preconditioningEner_0001 0;
BA_ "SystemSignalLongSymbol" SG_ 957 VCFRONT_preconditioningEner_0001 "VCFRONT_preconditioningEnergyLossSinceDrive";
BA_ "Confidence" SG_ 957 VCFRONT_cabinOverheatEnergy_0001 0;
BA_ "SystemSignalLongSymbol" SG_ 957 VCFRONT_cabinOverheatEnergy_0001 "VCFRONT_cabinOverheatEnergyLossSinceDrive";
BA_ "Confidence" SG_ 957 VCFRONT_mobileAppEnergyLoss_0001 0;
BA_ "SystemSignalLongSymbol" SG_ 957 VCFRONT_mobileAppEnergyLoss_0001 "VCFRONT_mobileAppEnergyLossSinceDrive";
BA_ "Confidence" SG_ 957 VCFRONT_summonStandbyEnergy_0001 0;
BA_ "SystemSignalLongSymbol" SG_ 957 VCFRONT_summonStandbyEnergy_0001 "VCFRONT_summonStandbyEnergyLossSinceDrive";
BA_ "Confidence" SG_ 957 VCFRONT_sentryModeEnergyLos_0001 0;
BA_ "SystemSignalLongSymbol" SG_ 957 VCFRONT_sentryModeEnergyLos_0001 "VCFRONT_sentryModeEnergyLossSinceDrive";
BA_ "Confidence" SG_ 957 VCFRONT_backgroundEnergyLos_0001 0;
BA_ "SystemSignalLongSymbol" SG_ 957 VCFRONT_backgroundEnergyLos_0001 "VCFRONT_backgroundEnergyLossSinceDrive";
BA_ "Confidence" SG_ 957 VCFRONT_evapDryingEnergyLos_0001 0;
BA_ "SystemSignalLongSymbol" SG_ 957 VCFRONT_evapDryingEnergyLos_0001 "VCFRONT_evapDryingEnergyLossSinceDrive";
BA_ "Confidence" SG_ 957 VCFRONT_userEnergyLossSinceCharg 0;
BA_ "SystemSignalLongSymbol" SG_ 957 VCFRONT_userEnergyLossSinceCharg "VCFRONT_userEnergyLossSinceCharge";
BA_ "Confidence" SG_ 957 VCFRONT_preconditioningEnergyLos 0;
BA_ "SystemSignalLongSymbol" SG_ 957 VCFRONT_preconditioningEnergyLos "VCFRONT_preconditioningEnergyLossSinceCharge";
BA_ "Confidence" SG_ 957 VCFRONT_cabinOverheatEnergyLossS 0;
BA_ "SystemSignalLongSymbol" SG_ 957 VCFRONT_cabinOverheatEnergyLossS "VCFRONT_cabinOverheatEnergyLossSinceCharge";
BA_ "Confidence" SG_ 957 VCFRONT_mobileAppEnergyLossSince 0;
BA_ "SystemSignalLongSymbol" SG_ 957 VCFRONT_mobileAppEnergyLossSince "VCFRONT_mobileAppEnergyLossSinceCharge";
BA_ "Confidence" SG_ 957 VCFRONT_summonStandbyEnergyLossS 0;
BA_ "SystemSignalLongSymbol" SG_ 957 VCFRONT_summonStandbyEnergyLossS "VCFRONT_summonStandbyEnergyLossSinceCharge";
BA_ "Confidence" SG_ 957 VCFRONT_sentryModeEnergyLossSinc 0;
BA_ "SystemSignalLongSymbol" SG_ 957 VCFRONT_sentryModeEnergyLossSinc "VCFRONT_sentryModeEnergyLossSinceCharge";
BA_ "Confidence" SG_ 957 VCFRONT_backgroundEnergyLossSinc 0;
BA_ "SystemSignalLongSymbol" SG_ 957 VCFRONT_backgroundEnergyLossSinc "VCFRONT_backgroundEnergyLossSinceCharge";
BA_ "Confidence" SG_ 957 VCFRONT_evapDryingEnergyLossSinc 0;
BA_ "SystemSignalLongSymbol" SG_ 957 VCFRONT_evapDryingEnergyLossSinc "VCFRONT_evapDryingEnergyLossSinceCharge";
BA_ "Confidence" SG_ 507 VCLEFT_TLCStatusIndex 1;
BA_ "Confidence" SG_ 507 VCLEFT_TLCTemperature 0;
BA_ "GenSigSNA" SG_ 507 VCLEFT_TLCTemperature "128";
BA_ "Confidence" SG_ 507 VCLEFT_TLCLeftTurnVoltage 0;
BA_ "GenSigSNA" SG_ 507 VCLEFT_TLCLeftTurnVoltage "255";
BA_ "Confidence" SG_ 507 VCLEFT_TLCRightTurnVoltage 0;
BA_ "GenSigSNA" SG_ 507 VCLEFT_TLCRightTurnVoltage "255";
BA_ "Confidence" SG_ 507 VCLEFT_TLCState_LeftTurn 0;
BA_ "GenSigSNA" SG_ 507 VCLEFT_TLCState_LeftTurn "5";
BA_ "Confidence" SG_ 507 VCLEFT_TLCState_RightTurn 0;
BA_ "GenSigSNA" SG_ 507 VCLEFT_TLCState_RightTurn "5";
BA_ "Confidence" SG_ 507 VCLEFT_TLCState_Tail 0;
BA_ "GenSigSNA" SG_ 507 VCLEFT_TLCState_Tail "5";
BA_ "Confidence" SG_ 507 VCLEFT_TLCState_Stop 0;
BA_ "GenSigSNA" SG_ 507 VCLEFT_TLCState_Stop "5";
BA_ "Confidence" SG_ 507 VCLEFT_TLCState_Fog 0;
BA_ "GenSigSNA" SG_ 507 VCLEFT_TLCState_Fog "5";
BA_ "Confidence" SG_ 507 VCLEFT_TLCState_Reverse 0;
BA_ "GenSigSNA" SG_ 507 VCLEFT_TLCState_Reverse "5";
BA_ "Confidence" SG_ 291 VCRIGHT_doorStatus2Index 1;
BA_ "Confidence" SG_ 291 VCRIGHT_frontLatchRelDuty 0;
BA_ "Confidence" SG_ 291 VCRIGHT_BPillarCameraHeaterState 0;
BA_ "GenSigSNA" SG_ 291 VCRIGHT_BPillarCameraHeaterState "0";
BA_ "Confidence" SG_ 291 VCRIGHT_doorLatchAjarSwitchVolta 0;
BA_ "SystemSignalLongSymbol" SG_ 291 VCRIGHT_doorLatchAjarSwitchVolta "VCRIGHT_doorLatchAjarSwitchVoltageF";
BA_ "Confidence" SG_ 291 VCRIGHT_doorLatchAjarSwitch_0001 0;
BA_ "SystemSignalLongSymbol" SG_ 291 VCRIGHT_doorLatchAjarSwitch_0001 "VCRIGHT_doorLatchAjarSwitchVoltageR";
BA_ "Confidence" SG_ 291 VCRIGHT_BPillarCameraHeaterCurre 0;
BA_ "GenSigSNA" SG_ 291 VCRIGHT_BPillarCameraHeaterCurre "63";
BA_ "SystemSignalLongSymbol" SG_ 291 VCRIGHT_BPillarCameraHeaterCurre "VCRIGHT_BPillarCameraHeaterCurrent";
BA_ "Confidence" SG_ 291 VCRIGHT_mirrorTiltXOffset 0;
BA_ "Confidence" SG_ 291 VCRIGHT_mirrorTiltYOffset 0;
BA_ "Confidence" SG_ 899 VCRIGHT_thsActive 0;
BA_ "Confidence" SG_ 899 VCRIGHT_thsTemperature 0;
BA_ "GenSigSNA" SG_ 899 VCRIGHT_thsTemperature "255";
BA_ "Confidence" SG_ 899 VCRIGHT_thsState 0;
BA_ "Confidence" SG_ 899 VCRIGHT_thsLINCurrentSchedule 0;
BA_ "Confidence" SG_ 899 VCRIGHT_thsDetected 0;
BA_ "Confidence" SG_ 899 VCRIGHT_thsHumidity 0;
BA_ "GenSigSNA" SG_ 899 VCRIGHT_thsHumidity "127";
BA_ "Confidence" SG_ 899 VCRIGHT_estimatedVehicleSituatio 0;
BA_ "SystemSignalLongSymbol" SG_ 899 VCRIGHT_estimatedVehicleSituatio "VCRIGHT_estimatedVehicleSituation";
BA_ "Confidence" SG_ 899 VCRIGHT_thsSolarLoadInfrared 0;
BA_ "GenSigSNA" SG_ 899 VCRIGHT_thsSolarLoadInfrared "1023";
BA_ "Confidence" SG_ 899 VCRIGHT_thsSolarLoadVisible 0;
BA_ "GenSigSNA" SG_ 899 VCRIGHT_thsSolarLoadVisible "1023";
BA_ "Confidence" SG_ 899 VCRIGHT_estimatedThsSolarLoad 0;
BA_ "GenSigSNA" SG_ 899 VCRIGHT_estimatedThsSolarLoad "1023";
BA_ "Confidence" SG_ 899 VCRIGHT_hvacFastLoggingEnabled 0;
BA_ "Confidence" SG_ 1066 VCSEC_TPMSSensorState0 0;
BA_ "Confidence" SG_ 1066 VCSEC_TPMSRSSI0 0;
BA_ "Confidence" SG_ 1066 VCSEC_TPMSConnectionTypeCurrent0 0;
BA_ "Confidence" SG_ 1066 VCSEC_TPMSConnectionTypeDesired0 0;
BA_ "Confidence" SG_ 1066 VCSEC_TPMSSensorState1 0;
BA_ "Confidence" SG_ 1066 VCSEC_TPMSRSSI1 0;
BA_ "Confidence" SG_ 1066 VCSEC_TPMSConnectionTypeCurrent1 0;
BA_ "Confidence" SG_ 1066 VCSEC_TPMSConnectionTypeDesired1 0;
BA_ "Confidence" SG_ 1066 VCSEC_TPMSSensorState2 0;
BA_ "Confidence" SG_ 1066 VCSEC_TPMSRSSI2 0;
BA_ "Confidence" SG_ 1066 VCSEC_TPMSConnectionTypeCurrent2 0;
BA_ "Confidence" SG_ 1066 VCSEC_TPMSConnectionTypeDesired2 0;
BA_ "Confidence" SG_ 1066 VCSEC_TPMSSensorState3 0;
BA_ "Confidence" SG_ 1066 VCSEC_TPMSRSSI3 0;
BA_ "Confidence" SG_ 1066 VCSEC_TPMSConnectionTypeCurrent3 0;
BA_ "Confidence" SG_ 1066 VCSEC_TPMSConnectionTypeDesired3 0;
BA_ "Confidence" SG_ 1066 VCSEC_TPMSSensorPresence0 0;
BA_ "Confidence" SG_ 1066 VCSEC_TPMSSensorPresence1 0;
BA_ "Confidence" SG_ 1066 VCSEC_TPMSSensorPresence2 0;
BA_ "Confidence" SG_ 1066 VCSEC_TPMSSensorPresence3 0;
BA_ "Confidence" SG_ 1824 VCSEC_ECUConfigCRC32 0;
BA_ "Confidence" SG_ 1824 VCSEC_autoWriteConfig 0;
BA_ "Confidence" SG_ 1824 VCSEC_requestForConfig 0;
VAL_ 1001 DAS_headlightRequest 3 "DAS_HEADLIGHT_REQUEST_INVALID" 2 "DAS_HEADLIGHT_REQUEST_TAIL_LIGHTS_ONLY" 1 "DAS_HEADLIGHT_REQUEST_ON" 0 "DAS_HEADLIGHT_REQUEST_OFF" ;
VAL_ 1001 DAS_hazardLightRequest 3 "DAS_REQUEST_HAZARDS_SNA" 2 "DAS_REQUEST_HAZARDS_ON_FAST" 1 "DAS_REQUEST_HAZARDS_ON" 0 "DAS_REQUEST_HAZARDS_OFF" ;
VAL_ 1001 DAS_wiperSpeed 15 "DAS_WIPER_SPEED_INVALID" 14 "DAS_WIPER_SPEED_14" 13 "DAS_WIPER_SPEED_13" 12 "DAS_WIPER_SPEED_12" 11 "DAS_WIPER_SPEED_11" 10 "DAS_WIPER_SPEED_10" 9 "DAS_WIPER_SPEED_9" 8 "DAS_WIPER_SPEED_8" 7 "DAS_WIPER_SPEED_7" 6 "DAS_WIPER_SPEED_6" 5 "DAS_WIPER_SPEED_5" 4 "DAS_WIPER_SPEED_4" 3 "DAS_WIPER_SPEED_3" 2 "DAS_WIPER_SPEED_2" 1 "DAS_WIPER_SPEED_1" 0 "DAS_WIPER_SPEED_OFF" ;
VAL_ 1001 DAS_turnIndicatorRequest 4 "DAS_TURN_INDICATOR_DEFER" 3 "DAS_TURN_INDICATOR_CANCEL" 2 "DAS_TURN_INDICATOR_RIGHT" 1 "DAS_TURN_INDICATOR_LEFT" 0 "DAS_TURN_INDICATOR_NONE" ;
VAL_ 1001 DAS_highLowBeamDecision 3 "DAS_HIGH_BEAM_SNA" 2 "DAS_HIGH_BEAM_ON" 1 "DAS_HIGH_BEAM_OFF" 0 "DAS_HIGH_BEAM_UNDECIDED" ;
VAL_ 1001 DAS_heaterRequest 2 "DAS_HEATER_ON" 1 "DAS_HEATER_OFF" 0 "DAS_HEATER_SNA" ;
VAL_ 1001 DAS_highLowBeamOffReason 5 "HIGH_BEAM_OFF_REASON_SNA" 4 "HIGH_BEAM_OFF_REASON_HEAD_LIGHT" 3 "HIGH_BEAM_OFF_REASON_AMBIENT_LIGHT" 2 "HIGH_BEAM_OFF_REASON_MOVING_RADAR_TARGET" 1 "HIGH_BEAM_OFF_REASON_MOVING_VISION_TARGET" 0 "HIGH_BEAM_ON" ;
VAL_ 1001 DAS_mirrorFoldRequest 3 "DAS_MIRROR_REQUEST_SNA" 2 "DAS_MIRROR_REQUEST_UNFOLD" 1 "DAS_MIRROR_REQUEST_FOLD" 0 "DAS_MIRROR_REQUEST_NONE" ;
VAL_ 1001 DAS_autoWiperState 5 "DAS_AUTO_WIPER_STATE_SNA" 4 "DAS_AUTO_WIPER_STATE_FAST_CONTINUOUS" 3 "DAS_AUTO_WIPER_STATE_SLOW_CONTINUOUS" 2 "DAS_AUTO_WIPER_STATE_FAST_INTERMITTENT" 1 "DAS_AUTO_WIPER_STATE_SLOW_INTERMITTENT" 0 "DAS_AUTO_WIPER_STATE_OFF" ;
VAL_ 1001 DAS_turnIndicatorRequestReason 24 "DAS_ACTIVE_SIMULTANEOUS_LANE_CHANGE_AVOIDANCE" 23 "DAS_ACTIVE_INFEASIBLE_KINEMATICS_LANE_CHANGE" 22 "DAS_ACTIVE_STAY_OUT_OF_RIGHTMOST_LANE_LANE_CHANGE" 21 "DAS_ACTIVE_AWAY_FROM_MERGE_LANE_CHANGE" 20 "DAS_ACTIVE_EXIT_RIGHT_LANE_LANE_CHANGE" 19 "DAS_ACTIVE_EXIT_PASSING_LANE_LANE_CHANGE" 18 "DAS_ACTIVE_INCORRECT_ROAD_SIDE_LANE_CHANGE" 17 "DAS_ACTIVE_STATIC_OBJECT_LANE_CHANGE" 15 "DAS_CANCEL_MANUAL_BLINKER" 14 "DAS_CANCEL_AUTO_PARK" 13 "DAS_ACTIVE_AUTO_PARK" 12 "DAS_CANCEL_SUMMMON" 11 "DAS_ACTIVE_SUMMMON" 10 "DAS_CANCEL_INTERSECTION" 9 "DAS_ACTIVE_INTERSECTION" 8 "DAS_ACTIVE_COMMANDED_LANE_CHANGE" 7 "DAS_CANCEL_MERGE" 6 "DAS_ACTIVE_MERGE" 5 "DAS_CANCEL_FORK" 4 "DAS_CANCEL_LANE_CHANGE" 3 "DAS_ACTIVE_FORK" 2 "DAS_ACTIVE_SPEED_LANE_CHANGE" 1 "DAS_ACTIVE_NAV_LANE_CHANGE" 0 "DAS_NONE" ;
VAL_ 1001 DAS_restrictDoorReleaseLeft 1 "RESTRICT_DOOR_RELEASE_ACTIVE" 0 "RESTRICT_DOOR_RELEASE_INACTIVE" ;
VAL_ 1001 DAS_restrictDoorReleaseRight 1 "RESTRICT_DOOR_RELEASE_ACTIVE" 0 "RESTRICT_DOOR_RELEASE_INACTIVE" ;
VAL_ 784 HVP_infoIndex 255 "END" 31 "SUBCOMPONENT_GITHASH" 30 "PACKAGE_SN_8_14" 29 "PACKAGE_SN_1_7" 27 "PACKAGE_PN_15_20" 26 "PACKAGE_PN_8_14" 25 "PACKAGE_PN_1_7" 23 "SUBCOMPONENT2" 22 "VARIANTCRC" 20 "UDS_PROTOCOL_BOOTCRC" 19 "VERSION_DEPRECATED" 18 "BOOTLOADER_GITHASH" 17 "APP_GITHASH" 16 "SUBCOMPONENT" 15 "BOOTLOADER_CRC" 14 "BOOTLOADER_SVN" 13 "APP_CRC" 11 "PCBAID_ASSYID_USAGEID" 10 "BUILD_HWID_COMPONENTID" 9 "DEPRECATED_9" 8 "DEPRECATED_8" 7 "DEPRECATED_7" 6 "DEPRECATED_6" 5 "DEPRECATED_5" 4 "DEPRECATED_4" 3 "DEPRECATED_3" 2 "DEPRECATED_2" 1 "DEPRECATED_1" 0 "DEPRECATED_0" ;
VAL_ 784 HVP_buildType 4 "INFO_MFG_BUILD" 3 "INFO_TRACEABLE_CI_BUILD" 2 "INFO_LOCAL_BUILD" 1 "INFO_PLATFORM_BUILD" 0 "INFO_UNKNOWN_BUILD" ;
VAL_ 941 ICR_infoIndex 255 "END" 31 "SUBCOMPONENT_GITHASH" 30 "PACKAGE_SN_8_14" 29 "PACKAGE_SN_1_7" 27 "PACKAGE_PN_15_20" 26 "PACKAGE_PN_8_14" 25 "PACKAGE_PN_1_7" 23 "SUBCOMPONENT2" 22 "VARIANTCRC" 20 "UDS_PROTOCOL_BOOTCRC" 19 "VERSION_DEPRECATED" 18 "BOOTLOADER_GITHASH" 17 "APP_GITHASH" 16 "SUBCOMPONENT" 15 "BOOTLOADER_CRC" 14 "BOOTLOADER_SVN" 13 "APP_CRC" 11 "PCBAID_ASSYID_USAGEID" 10 "BUILD_HWID_COMPONENTID" 9 "DEPRECATED_9" 8 "DEPRECATED_8" 7 "DEPRECATED_7" 6 "DEPRECATED_6" 5 "DEPRECATED_5" 4 "DEPRECATED_4" 3 "DEPRECATED_3" 2 "DEPRECATED_2" 1 "DEPRECATED_1" 0 "DEPRECATED_0" ;
VAL_ 941 ICR_infoBuildType 4 "INFO_MFG_BUILD" 3 "INFO_TRACEABLE_CI_BUILD" 2 "INFO_LOCAL_BUILD" 1 "INFO_PLATFORM_BUILD" 0 "INFO_UNKNOWN_BUILD" ;
VAL_ 964 PCS_infoIndex 255 "END" 31 "SUBCOMPONENT_GITHASH" 30 "PACKAGE_SN_8_14" 29 "PACKAGE_SN_1_7" 27 "PACKAGE_PN_15_20" 26 "PACKAGE_PN_8_14" 25 "PACKAGE_PN_1_7" 23 "SUBCOMPONENT2" 22 "VARIANTCRC" 20 "UDS_PROTOCOL_BOOTCRC" 19 "VERSION_DEPRECATED" 18 "BOOTLOADER_GITHASH" 17 "APP_GITHASH" 16 "SUBCOMPONENT" 15 "BOOTLOADER_CRC" 14 "BOOTLOADER_SVN" 13 "APP_CRC" 11 "PCBAID_ASSYID_USAGEID" 10 "BUILD_HWID_COMPONENTID" 9 "DEPRECATED_9" 8 "DEPRECATED_8" 7 "DEPRECATED_7" 6 "DEPRECATED_6" 5 "DEPRECATED_5" 4 "DEPRECATED_4" 3 "DEPRECATED_3" 2 "DEPRECATED_2" 1 "DEPRECATED_1" 0 "DEPRECATED_0" ;
VAL_ 964 PCS_buildType 4 "INFO_MFG_BUILD" 3 "INFO_TRACEABLE_CI_BUILD" 2 "INFO_LOCAL_BUILD" 1 "INFO_PLATFORM_BUILD" 0 "INFO_UNKNOWN_BUILD" ;
VAL_ 816 SCCM_infoIndex 255 "END" 20 "UDS_PROTOCOL_BOOTCRC" 18 "BOOTLOADER_SVNHASH" 17 "APP_SVNHASH" 16 "SUBCOMPONENT1" 14 "BOOTLOADER_SVN" 13 "APP_CRC" 11 "PCBAID_ASSYID_USAGEID" 10 "BUILD_HWID_COMPONENTID" ;
VAL_ 816 SCCM_infoBuildType 4 "INFO_MFG_BUILD" 3 "INFO_TRACEABLE_CI_BUILD" 2 "INFO_LOCAL_BUILD" 1 "INFO_PLATFORM_BUILD" 0 "INFO_UNKNOWN_BUILD" ;
VAL_ 663 UI_adaptiveRideRequest 3 "ADAPTIVE_RIDE_REQUEST_ADVANCED" 2 "ADAPTIVE_RIDE_REQUEST_SPORT" 1 "ADAPTIVE_RIDE_REQUEST_AUTO" 0 "ADAPTIVE_RIDE_REQUEST_COMFORT" ;
VAL_ 663 UI_geofenceLevelingRequest 5 "GEOFENCE_LEVELING_REQUEST_SNA" 4 "GEOFENCE_LEVELING_REQUEST_VERY_HIGH_PERSIST" 3 "GEOFENCE_LEVELING_REQUEST_HIGH_PERSIST" 2 "GEOFENCE_LEVELING_REQUEST_VERY_HIGH_TEMPORARY" 1 "GEOFENCE_LEVELING_REQUEST_HIGH_TEMPORARY" 0 "GEOFENCE_LEVELING_REQUEST_NONE" ;
VAL_ 957 VCFRONT_energyLossIndex 4 "SINCE_LAST_CHARGE2" 3 "SINCE_LAST_CHARGE" 2 "SINCE_LAST_DRIVE2" 1 "SINCE_LAST_DRIVE" 0 "STATUS" ;
VAL_ 507 VCLEFT_TLCStatusIndex 2 "INVALID" 1 "1" 0 "0" ;
VAL_ 507 VCLEFT_TLCTemperature -128 "SNA" ;
VAL_ 507 VCLEFT_TLCLeftTurnVoltage 255 "SNA" ;
VAL_ 507 VCLEFT_TLCRightTurnVoltage 255 "SNA" ;
VAL_ 507 VCLEFT_TLCState_LeftTurn 5 "VCLEFT_TLC_LIGHT_STATE_SNA" 4 "VCLEFT_TLC_LIGHT_STATE_FAULT" 3 "VCLEFT_TLC_LIGHT_STATE_ON_WITH_LOAD" 2 "VCLEFT_TLC_LIGHT_STATE_ON_WITHOUT_LOAD" 1 "VCLEFT_TLC_LIGHT_STATE_OFF_WITH_LOAD" 0 "VCLEFT_TLC_LIGHT_STATE_OFF_WITHOUT_LOAD" ;
VAL_ 507 VCLEFT_TLCState_RightTurn 5 "VCLEFT_TLC_LIGHT_STATE_SNA" 4 "VCLEFT_TLC_LIGHT_STATE_FAULT" 3 "VCLEFT_TLC_LIGHT_STATE_ON_WITH_LOAD" 2 "VCLEFT_TLC_LIGHT_STATE_ON_WITHOUT_LOAD" 1 "VCLEFT_TLC_LIGHT_STATE_OFF_WITH_LOAD" 0 "VCLEFT_TLC_LIGHT_STATE_OFF_WITHOUT_LOAD" ;
VAL_ 507 VCLEFT_TLCState_Tail 5 "VCLEFT_TLC_LIGHT_STATE_SNA" 4 "VCLEFT_TLC_LIGHT_STATE_FAULT" 3 "VCLEFT_TLC_LIGHT_STATE_ON_WITH_LOAD" 2 "VCLEFT_TLC_LIGHT_STATE_ON_WITHOUT_LOAD" 1 "VCLEFT_TLC_LIGHT_STATE_OFF_WITH_LOAD" 0 "VCLEFT_TLC_LIGHT_STATE_OFF_WITHOUT_LOAD" ;
VAL_ 507 VCLEFT_TLCState_Stop 5 "VCLEFT_TLC_LIGHT_STATE_SNA" 4 "VCLEFT_TLC_LIGHT_STATE_FAULT" 3 "VCLEFT_TLC_LIGHT_STATE_ON_WITH_LOAD" 2 "VCLEFT_TLC_LIGHT_STATE_ON_WITHOUT_LOAD" 1 "VCLEFT_TLC_LIGHT_STATE_OFF_WITH_LOAD" 0 "VCLEFT_TLC_LIGHT_STATE_OFF_WITHOUT_LOAD" ;
VAL_ 507 VCLEFT_TLCState_Fog 5 "VCLEFT_TLC_LIGHT_STATE_SNA" 4 "VCLEFT_TLC_LIGHT_STATE_FAULT" 3 "VCLEFT_TLC_LIGHT_STATE_ON_WITH_LOAD" 2 "VCLEFT_TLC_LIGHT_STATE_ON_WITHOUT_LOAD" 1 "VCLEFT_TLC_LIGHT_STATE_OFF_WITH_LOAD" 0 "VCLEFT_TLC_LIGHT_STATE_OFF_WITHOUT_LOAD" ;
VAL_ 507 VCLEFT_TLCState_Reverse 5 "VCLEFT_TLC_LIGHT_STATE_SNA" 4 "VCLEFT_TLC_LIGHT_STATE_FAULT" 3 "VCLEFT_TLC_LIGHT_STATE_ON_WITH_LOAD" 2 "VCLEFT_TLC_LIGHT_STATE_ON_WITHOUT_LOAD" 1 "VCLEFT_TLC_LIGHT_STATE_OFF_WITH_LOAD" 0 "VCLEFT_TLC_LIGHT_STATE_OFF_WITHOUT_LOAD" ;
VAL_ 291 VCRIGHT_doorStatus2Index 1 "MUX1" 0 "MUX0" ;
VAL_ 291 VCRIGHT_BPillarCameraHeaterState 4 "HEATER_STATE_FAULT" 3 "HEATER_STATE_OFF_UNAVAILABLE" 2 "HEATER_STATE_OFF" 1 "HEATER_STATE_ON" 0 "HEATER_STATE_SNA" ;
VAL_ 291 VCRIGHT_BPillarCameraHeaterCurre 63 "SNA" ;
VAL_ 899 VCRIGHT_thsTemperature 255 "SNA" ;
VAL_ 899 VCRIGHT_thsState 4 "IDLE" 3 "WAIT_CRC_RESPONSE" 2 "WAIT_CRC_REQUEST" 1 "CONFIG" 0 "INIT" ;
VAL_ 899 VCRIGHT_thsLINCurrentSchedule 7 "OTHER" 3 "DIAGNOSTIC" 2 "CONFIG" 1 "MAIN" 0 "OFF" ;
VAL_ 899 VCRIGHT_thsHumidity 127 "SNA" ;
VAL_ 899 VCRIGHT_estimatedVehicleSituatio 2 "VEHICLE_SITUATION_OUTDOOR" 1 "VEHICLE_SITUATION_INDOOR" 0 "VEHICLE_SITUATION_UNKNOWN" ;
VAL_ 899 VCRIGHT_thsSolarLoadInfrared 1023 "SNA" ;
VAL_ 899 VCRIGHT_thsSolarLoadVisible 1023 "SNA" ;
VAL_ 899 VCRIGHT_estimatedThsSolarLoad 1023 "SNA" ;
VAL_ 1066 VCSEC_TPMSSensorState0 5 "SENSOR_WAIT_FOR_NEXT_ADV" 4 "SENSOR_DISCONNECTING" 3 "SENSOR_CONNECTED" 2 "SENSOR_WAIT_FOR_CONN" 1 "SENSOR_WAIT_FOR_ADV" 0 "SENSOR_NOT_PAIRED" ;
VAL_ 1066 VCSEC_TPMSConnectionTypeCurrent0 3 "CONNECTIONTYPE_FAST_SLAVE_LATENCY" 2 "CONNECTIONTYPE_UNKNOWN" 1 "CONNECTIONTYPE_SLOW" 0 "CONNECTIONTYPE_FAST" ;
VAL_ 1066 VCSEC_TPMSConnectionTypeDesired0 3 "CONNECTIONTYPE_FAST_SLAVE_LATENCY" 2 "CONNECTIONTYPE_UNKNOWN" 1 "CONNECTIONTYPE_SLOW" 0 "CONNECTIONTYPE_FAST" ;
VAL_ 1066 VCSEC_TPMSSensorState1 5 "SENSOR_WAIT_FOR_NEXT_ADV" 4 "SENSOR_DISCONNECTING" 3 "SENSOR_CONNECTED" 2 "SENSOR_WAIT_FOR_CONN" 1 "SENSOR_WAIT_FOR_ADV" 0 "SENSOR_NOT_PAIRED" ;
VAL_ 1066 VCSEC_TPMSConnectionTypeCurrent1 3 "CONNECTIONTYPE_FAST_SLAVE_LATENCY" 2 "CONNECTIONTYPE_UNKNOWN" 1 "CONNECTIONTYPE_SLOW" 0 "CONNECTIONTYPE_FAST" ;
VAL_ 1066 VCSEC_TPMSConnectionTypeDesired1 3 "CONNECTIONTYPE_FAST_SLAVE_LATENCY" 2 "CONNECTIONTYPE_UNKNOWN" 1 "CONNECTIONTYPE_SLOW" 0 "CONNECTIONTYPE_FAST" ;
VAL_ 1066 VCSEC_TPMSSensorState2 5 "SENSOR_WAIT_FOR_NEXT_ADV" 4 "SENSOR_DISCONNECTING" 3 "SENSOR_CONNECTED" 2 "SENSOR_WAIT_FOR_CONN" 1 "SENSOR_WAIT_FOR_ADV" 0 "SENSOR_NOT_PAIRED" ;
VAL_ 1066 VCSEC_TPMSConnectionTypeCurrent2 3 "CONNECTIONTYPE_FAST_SLAVE_LATENCY" 2 "CONNECTIONTYPE_UNKNOWN" 1 "CONNECTIONTYPE_SLOW" 0 "CONNECTIONTYPE_FAST" ;
VAL_ 1066 VCSEC_TPMSConnectionTypeDesired2 3 "CONNECTIONTYPE_FAST_SLAVE_LATENCY" 2 "CONNECTIONTYPE_UNKNOWN" 1 "CONNECTIONTYPE_SLOW" 0 "CONNECTIONTYPE_FAST" ;
VAL_ 1066 VCSEC_TPMSSensorState3 5 "SENSOR_WAIT_FOR_NEXT_ADV" 4 "SENSOR_DISCONNECTING" 3 "SENSOR_CONNECTED" 2 "SENSOR_WAIT_FOR_CONN" 1 "SENSOR_WAIT_FOR_ADV" 0 "SENSOR_NOT_PAIRED" ;
VAL_ 1066 VCSEC_TPMSConnectionTypeCurrent3 3 "CONNECTIONTYPE_FAST_SLAVE_LATENCY" 2 "CONNECTIONTYPE_UNKNOWN" 1 "CONNECTIONTYPE_SLOW" 0 "CONNECTIONTYPE_FAST" ;
VAL_ 1066 VCSEC_TPMSConnectionTypeDesired3 3 "CONNECTIONTYPE_FAST_SLAVE_LATENCY" 2 "CONNECTIONTYPE_UNKNOWN" 1 "CONNECTIONTYPE_SLOW" 0 "CONNECTIONTYPE_FAST" ;
VAL_ 1066 VCSEC_TPMSSensorPresence0 2 "PRESENT" 1 "NOT_PRESENT" 0 "NOT_PAIRED" ;
VAL_ 1066 VCSEC_TPMSSensorPresence1 2 "PRESENT" 1 "NOT_PRESENT" 0 "NOT_PAIRED" ;
VAL_ 1066 VCSEC_TPMSSensorPresence2 2 "PRESENT" 1 "NOT_PRESENT" 0 "NOT_PAIRED" ;
VAL_ 1066 VCSEC_TPMSSensorPresence3 2 "PRESENT" 1 "NOT_PRESENT" 0 "NOT_PAIRED" ;
